VERSION "Excel 2 DBC"

NS_ :

BS_:

BU_: Tank_Sensor1

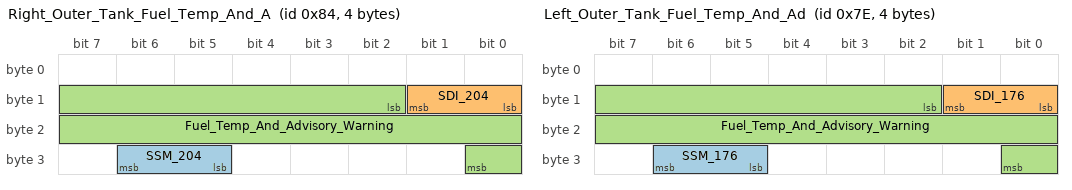
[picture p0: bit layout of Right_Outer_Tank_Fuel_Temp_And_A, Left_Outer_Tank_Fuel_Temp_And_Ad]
BO_ 132 Right_Outer_Tank_Fuel_Temp_And_A: 4 Tank_Sensor1
 SG_ SSM_204 : 29|2@1+ (1,0) [0|3] "" Vector__XXX
 SG_ SDI_204 : 8|2@1+ (1,0) [0|3] "" Vector__XXX
 SG_ Fuel_Temp_And_Advisory_Warning : 10|15@1- (0.25,0) [-512|512] "" Vector__XXX

BO_ 126 Left_Outer_Tank_Fuel_Temp_And_Ad: 4 Tank_Sensor1
 SG_ SSM_176 : 29|2@1+ (1,0) [0|3] "" Vector__XXX
 SG_ SDI_176 : 8|2@1+ (1,0) [0|3] "" Vector__XXX
 SG_ Fuel_Temp_And_Advisory_Warning : 10|15@1- (0.25,0) [-512|512] "" Vector__XXX

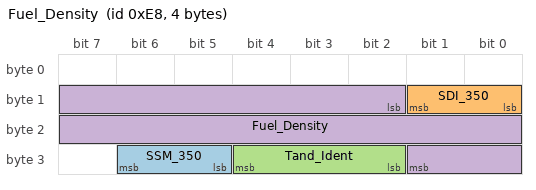
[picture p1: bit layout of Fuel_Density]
BO_ 232 Fuel_Density: 4 Tank_Sensor1
 SG_ SSM_350 : 29|2@1+ (1,0) [0|3] "" Vector__XXX
 SG_ SDI_350 : 8|2@1+ (1,0) [0|3] "" Vector__XXX
 SG_ Tand_Ident : 26|3@1+ (1,0) [0|7] "" Vector__XXX
 SG_ Fuel_Density : 10|16@1- (0.0001,0) [0|1] "kg/l" Vector__XXX

VAL_ 132 SSM_204 0 "Normal Operation " 1 "NCD" 2 "Functional Test" 3 "Failure Warning ";
VAL_ 126 SSM_176 0 "Normal Operation " 1 "NCD" 2 "Functional Test" 3 "Failure Warning ";
VAL_ 232 SSM_350 0 "Normal Operation " 1 "NCD" 2 "Functional Test" 3 "Failure Warning ";
